# f2838x_cm_cm_i2c_write_regs register map
Vendor: Texas Instruments
Peripheral module from a debugger description file (folder C2000).
Address unit: 16 bits
Registers are 32-bit, read-write, no defined reset value unless marked. A register's access mark holds for its fields unless they carry their own. Offsets are as the file gives them; lines under a group give offsets from that group; [hi:lo] are bit positions; {n}, {i} and the like mark numbered series; 'fields as' and 'values as' point back to an identical list; <NAME> marks a mode.

## CM_I2C_WRITE_REGS — CM I2C WRITE Registers
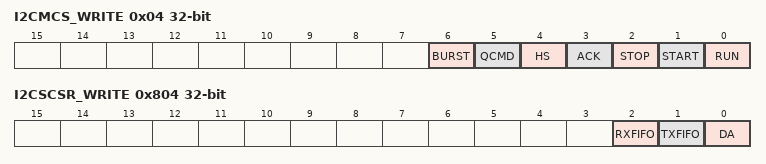
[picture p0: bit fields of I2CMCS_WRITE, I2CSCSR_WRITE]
0x04 I2CMCS_WRITE — I2C Master Control/Status
  [6] BURST — Burst Enable
  [5] QCMD — Quick Command
  [4] HS — High-Speed Enable
  [3] ACK — Data Acknowledge Enable
  [2] STOP — Generate STOP
  [1] START — Generate START
  [0] RUN — I2C Master Enable
0x804 I2CSCSR_WRITE — I2C Slave Control/Status
  [2] RXFIFO — RX FIFO Enable
  [1] TXFIFO — TX FIFO Enable
  [0] DA — Device Active
0xF00 I2CFIFODATATX
  [7:0] DATA — I2C TX FIFO Write Data Byte
